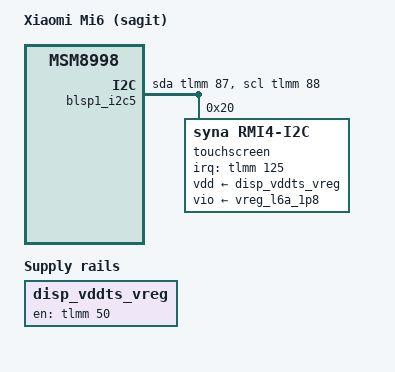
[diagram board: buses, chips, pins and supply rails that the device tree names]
// SPDX-License-Identifier: GPL-2.0
/* Copyright (c) 2016, The Linux Foundation. All rights reserved. */

/dts-v1/;

#include "msm8998-xiaomi-sagit.dtsi"

/ {
	model = "Xiaomi Mi6 (sagit)";
	compatible = "qcom,msm8998-mtp", "qcom,msm8998", "qcom,mtp";

	qcom,board-id = <30 0>;
};

&soc {
	disp_vddts_vreg: disp_vddts_vreg {
		compatible = "regulator-fixed";
		regulator-name = "disp_vddts_vreg";
		startup-delay-us = <4000>;
		enable-active-high;
		regulator-boot-on;
		gpio = <&tlmm 50 0>;
	};
};

&blsp1_i2c5 {
	compatible = "i2c-gpio";
	sda-gpios = <&tlmm 87 (GPIO_ACTIVE_HIGH|GPIO_OPEN_DRAIN)>;
	scl-gpios = <&tlmm 88 (GPIO_ACTIVE_HIGH|GPIO_OPEN_DRAIN)>;
	i2c-gpio,delay-us = <5>;	/* 5~=100 kHz */
	#address-cells = <1>;
	#size-cells = <0>;
	status = "okay";
	touchscreen: synaptics-rmi4-i2c@20 {
		compatible = "syna,rmi4-i2c";
		reg = <0x20>;
		#address-cells = <1>;
		#size-cells = <0>;
		interrupts-extended = <&tlmm 125 0x2008>; // IRQF_ONESHOT|IRQF_TRIGGER_LOW
		pinctrl-names = "pmx_ts_active", "pmx_ts_suspend";
		pinctrl-0 = <&ts_active>;
		pinctrl-1 = <&ts_int_suspend &ts_reset_suspend>;
		vdd-supply = <&disp_vddts_vreg>;
		vio-supply = <&vreg_l6a_1p8>;
		syna,reset-delay-ms = <200>;
		syna,startup-delay-ms = <200>;

		rmi4-f01@1 {
			reg = <0x1>;
			syna,nosleep-mode = <1>;
		};

		rmi4_f12: rmi4-f12@12 {
			reg = <0x12>;
			touchscreen-x-mm = <64>;
			touchscreen-y-mm = <116>;
			syna,sensor-type = <1>;
			syna,rezero-wait-ms = <200>;
		};
	};
};
